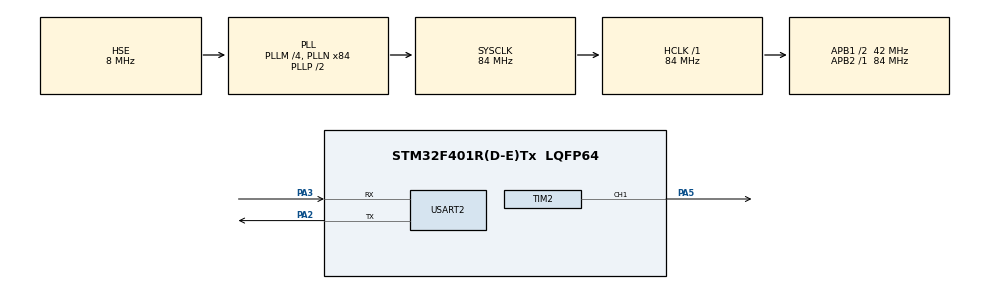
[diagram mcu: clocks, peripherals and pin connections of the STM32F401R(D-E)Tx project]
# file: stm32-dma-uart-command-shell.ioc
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Dma.Request0=USART2_RX
Dma.Request1=USART2_TX
Dma.USART2_RX.0.Direction=DMA_PERIPH_TO_MEMORY
Dma.USART2_RX.0.FIFOMode=DMA_FIFOMODE_DISABLE
Dma.USART2_RX.0.Instance=DMA1_Stream5
Dma.USART2_RX.0.MemDataAlignment=DMA_MDATAALIGN_BYTE
Dma.USART2_RX.0.MemInc=DMA_MINC_ENABLE
Dma.USART2_RX.0.Mode=DMA_CIRCULAR
Dma.USART2_RX.0.PeriphDataAlignment=DMA_PDATAALIGN_BYTE
Dma.USART2_RX.0.PeriphInc=DMA_PINC_DISABLE
Dma.USART2_RX.0.Priority=DMA_PRIORITY_LOW
Dma.USART2_TX.1.Direction=DMA_MEMORY_TO_PERIPH
Dma.USART2_TX.1.FIFOMode=DMA_FIFOMODE_DISABLE
Dma.USART2_TX.1.Instance=DMA1_Stream6
Dma.USART2_TX.1.MemDataAlignment=DMA_MDATAALIGN_BYTE
Dma.USART2_TX.1.MemInc=DMA_MINC_ENABLE
Dma.USART2_TX.1.Mode=DMA_NORMAL
Dma.USART2_TX.1.PeriphDataAlignment=DMA_PDATAALIGN_BYTE
Dma.USART2_TX.1.PeriphInc=DMA_PINC_DISABLE
Dma.USART2_TX.1.Priority=DMA_PRIORITY_LOW
Mcu.Family=STM32F4
Mcu.Name=STM32F401R(D-E)Tx
Mcu.Package=LQFP64
NVIC.DMA1_Stream5_IRQn=true\:0\:0\:false\:false\:true\:false\:true\:true
NVIC.DMA1_Stream6_IRQn=true\:0\:0\:false\:false\:true\:false\:true\:true
NVIC.PriorityGroup=NVIC_PRIORITYGROUP_4
NVIC.TIM2_IRQn=true\:0\:0\:false\:false\:true\:true\:true\:true
NVIC.TIM3_IRQn=true\:0\:0\:false\:false\:true\:true\:true\:true
NVIC.USART2_IRQn=true\:0\:0\:false\:false\:true\:true\:true\:true
PA13.Mode=Serial_Wire
PA13.Signal=SYS_JTMS-SWDIO
PA14.Mode=Serial_Wire
PA14.Signal=SYS_JTCK-SWCLK
PA2.Mode=Asynchronous
PA2.Signal=USART2_TX
PA3.Mode=Asynchronous
PA3.Signal=USART2_RX
PA5.Signal=S_TIM2_CH1_ETR
PH0\ -\ OSC_IN.Mode=HSE-External-Oscillator
PH0\ -\ OSC_IN.Signal=RCC_OSC_IN
PH1\ -\ OSC_OUT.Mode=HSE-External-Oscillator
PH1\ -\ OSC_OUT.Signal=RCC_OSC_OUT
ProjectManager.HeapSize=0x200
ProjectManager.StackSize=0x400
ProjectManager.TargetToolchain=STM32CubeIDE
RCC.48MHZClocksFreq_Value=42000000
RCC.AHBFreq_Value=84000000
RCC.APB1CLKDivider=RCC_HCLK_DIV2
RCC.APB1Freq_Value=42000000
RCC.APB1TimFreq_Value=84000000
RCC.APB2Freq_Value=84000000
RCC.APB2TimFreq_Value=84000000
RCC.CortexFreq_Value=84000000
RCC.HCLKFreq_Value=84000000
RCC.HSE_VALUE=8000000
RCC.HSI_VALUE=16000000
RCC.LSE_VALUE=32768
RCC.PLLM=4
RCC.PLLN=84
RCC.PLLSourceVirtual=RCC_PLLSOURCE_HSE
RCC.SYSCLKFreq_VALUE=84000000
RCC.SYSCLKSource=RCC_SYSCLKSOURCE_PLLCLK
RCC.VCOOutputFreq_Value=168000000
SH.S_TIM2_CH1_ETR.0=TIM2_CH1,PWM Generation1 CH1
TIM2.AutoReloadPreload=TIM_AUTORELOAD_PRELOAD_ENABLE
TIM2.Channel-PWM\ Generation1\ CH1=TIM_CHANNEL_1
TIM2.Period=99
TIM2.Prescaler=839
TIM2.Pulse-PWM\ Generation1\ CH1=3250
TIM3.AutoReloadPreload=TIM_AUTORELOAD_PRELOAD_ENABLE
TIM3.Period=4999
TIM3.Prescaler=8399
USART2.VirtualMode=VM_ASYNC
VP_TIM2_VS_ClockSourceINT.Mode=Internal
VP_TIM3_VS_ClockSourceINT.Mode=Internal
board=custom

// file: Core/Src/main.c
/* USER CODE BEGIN Header */
/**
  ******************************************************************************
  * @file           : main.c
  * @brief          : UART command shell using DMA, between STM32F401RE and St-Link virtual COM port.
  * 				  Button Input.
  * @author			: Omar Ahmed
  ******************************************************************************
  * @details
  * An interactive command shell giving users control over the on-board LED (LD2, PA5)
  * blink rate (ms) and brightness (PWM)) independently.
  * TIM2_CH1 drives the PWM for brightness, and TIM3 sets the blink interval in milliseconds.
  * In addition, it creates feedback responses and status messages.
  *
  * Communication is handled through DMA1 stream 6 for TX and stream 5 for RX,
  * which operates in circular mode, storing the received messages in a ring buffer.
  * The end of each message is detected by the USART IDLE interrupt.
  *
  * Commands:
  * - help
  * - pwm <0-100>
  * - blink <ms>
  * - status
  *
  * Target: NUCLEO-F401RE (STM32F401RE, ARM Cortex-M4, 84 MHz)
  *
  *
  ******************************************************************************
  */
/* USER CODE END Header */
#include "main.h"

/* USER CODE BEGIN Includes */
#include <string.h>		// Byte and string manipulation
#include <stdio.h>		// Declares vsnprintf, used in shell_printf
#include <stdarg.h>		// Standard arguments, machinery for variadic functions.
#include <stdlib.h>		// Standard library.
/* USER CODE END Includes */

/* USER CODE BEGIN PD */
#define RX_BUFFER_SIZE	64
#define TX_BUFFER_SIZE	256
#define MSG_LEN_MAX	64
#define BLINK_MS_MAX	6553		// TIM3 ARR is 16-bit --> 65535 // 1 ARR

/* USER CODE END PD */

TIM_HandleTypeDef htim2;
TIM_HandleTypeDef htim3;

UART_HandleTypeDef huart2;
DMA_HandleTypeDef hdma_usart2_rx;
DMA_HandleTypeDef hdma_usart2_tx;

/* USER CODE BEGIN PV */
// UART receive
extern volatile uint8_t rx_ready;
static uint8_t rx_buffer[RX_BUFFER_SIZE];
static char tx_buffer[TX_BUFFER_SIZE];

static volatile uint16_t rx_tail = 0;
static volatile uint16_t rx_head = 0;

static char rx_msg[MSG_LEN_MAX];
static uint16_t rx_msg_len = 0;

// LED state
static volatile uint8_t blink_on = 1;
static volatile uint16_t blink_ms = 0;	// Size needs to match resigters of TIM3
static volatile uint32_t duty_cycle = 50;

/* USER CODE END PV */

void SystemClock_Config(void);
static void MX_GPIO_Init(void);
static void MX_DMA_Init(void);
static void MX_TIM2_Init(void);
static void MX_USART2_UART_Init(void);
static void MX_TIM3_Init(void);
/* USER CODE BEGIN PFP */
void SystemClock_Config(void);
static void MX_GPIO_Init(void);
static void MX_DMA_Init(void);
static void MX_TIM2_Init(void);
static void MX_USART2_UART_Init(void);
static void MX_TIM3_Init(void);
static void UART_Recieve_Start(void);
static void shell_poll(void);
static void shell_execute(char *msg);
static void shell_printf(const char *msg, ...);		// ... is ellipsis. variadic function --> accepts any number of additional arguments
static int parse_int(char *str, uint32_t *val);
static void led_set_pwm(void);
static void led_set_blink(uint16_t ms);
/* USER CODE BEGIN PFP */
/* USER CODE END PFP */

/* USER CODE BEGIN 0 */

/**
  * @brief  Pol what is received in rx_buffer and hand it to shell_execute.
  */
static void shell_poll(void){
	// Buffer size - NDTR, to get where the recieve msg stopped.
	// NDTR is updated continously.
	rx_head = RX_BUFFER_SIZE - (uint16_t)__HAL_DMA_GET_COUNTER(huart2.hdmarx);

	while (rx_tail != rx_head){			// tail = head when a msg is complete

		char c = rx_buffer[rx_tail];
		rx_tail = (rx_tail+1) % RX_BUFFER_SIZE; 	// Increment tail. Wrap at buffer end.

		if (c == '\r' || c == '\n'){		// When a msg is done
			if (rx_msg_len>0){
				rx_msg[rx_msg_len]= '\0';
				shell_execute(rx_msg);
				rx_msg_len = 0;
			}
		}
		else if (rx_msg_len < (MSG_LEN_MAX - 1)){
			rx_msg[rx_msg_len] = c;
			rx_msg_len++;
		}
		else{
			rx_msg_len = 0;	// Clear the rest of the line in overflow msgs
		}
	}
}

/**
  * @brief  Chech content of received msg, act on it, and print a response.
  */
void static shell_execute(char *msg){

	uint32_t value = 0;		// stroul return unsigned long, which is 32 bits on ARM32 M4

	// Check msg
	// help
	if(strncmp(msg, "help",4)==0){
		shell_printf("\r\n"
					"pwm <0-100>		brightness %% duty cycle \r\n"
					"blink <ms>		blink half-period, 0 = steady on\r\n"
					"status			current settings\r\n"
					"help			this text\r\n\r\n");
	} // pmw <0-100>
	else if (strncmp(msg, "pwm", 3)==0){
		if(!parse_int(msg+3, &value) || value > 100){
			shell_printf("Error: invalid pwm value, expects <0-100>!\r\n\r\n");
		}
		else if(value<=100){
			duty_cycle = value;
			led_set_pwm();
			shell_printf("Brightness set to %u%%!\r\n\r\n", duty_cycle);
		}

	} // blink <0-100>
	else if (strncmp(msg, "blink",5)==0){
		if (!parse_int(msg+5, &value) || value>	6553){		// TIM3 ARR is 16-bit --> 65535 // 1 ARR)
			shell_printf("Error: invalid brightness, expects 0-%u\r\n\r\n", BLINK_MS_MAX);
		}
		else if(value == 0){
			led_set_blink(0);
			shell_printf("Blinking off!\r\n\r\n");

		}
		else{
			led_set_blink((uint16_t) value);
			shell_printf("Blink half-period set to %u ms!\r\n\r\n", value);
		}
	} // status
	else if (strncmp(msg, "status", 6)==0){
		shell_printf("Brightness: %u%%\r\n", duty_cycle);
		shell_printf("Blink half-period: %u ms", blink_ms);

	}
	else{
		shell_printf("Error: unknown command!\r\n\r\n");
	}
}

/**
  * @brief  Parse a decimal value from a string and reject any trailing junk
  * @retval int, 1 on success, 0 on failure.
  */
static int parse_int(char *str, uint32_t *val){

	uint32_t v;		// uint32_t is same size as unsigned long on Cortex M4
	char *end;

	while (*str == ' '){
		str++;
	}
	if(*str<'0' || *str>'9'){
		return 0;
	}

	v=strtoul(str, &end, 10);

	while (*end == ' '){
		end++;
	}

	if (*end!='\0'){
		return 0;

	}

	*val = v;
	return 1;
}

/**
  * @brief  Formats a message and hand it to the TX DMA.
  */

static void shell_printf(const char *str, ...){

    va_list args;   // A type for handling the arguments represented by ..., it iterates over the additional arguments
    int len;

    while (huart2.gState != HAL_UART_STATE_READY){
        // Wait until UART is ready for another operation after the latest HAL_UART_Transmit_DMA
        // Acceptable because it is only called in the main loop
    }

    // Intialize args --> args-> first agrument after str (the last named argument of the function)
    va_start(args, str);        // Gives vsnprint access to the arguments supplied through ...

    // Formulate the arguments into a string buffer with a max.
    len = vsnprintf(tx_buffer, TX_BUFFER_SIZE, str, args);        // Difference between snprintf is that it accepts vardiac (accepts additional arguments)
                                                               // Len recieves the bytes written or would have been written if the buffer is not long enough in the buffer. (minus 1(\0))
    va_end(args);      // Finished using va_start
    if (len > 0){
        if(len> (int) TX_BUFFER_SIZE){
            len = (int) TX_BUFFER_SIZE;
        }
        // Starts the transmission and returns before all the bytes have physically been transmitted.
        HAL_UART_Transmit_DMA(&huart2, (uint8_t*)tx_buffer, (uint16_t) len);
    }

}

/**
  * @brief  Updates the PWM duty cycle in the capture compare register
  */
static void led_set_pwm(void){
    uint32_t arr = __HAL_TIM_GET_AUTORELOAD(&htim2);
    uint32_t crr = 0;

    if(blink_on){
        crr = ((arr+1)*(uint32_t)duty_cycle/100);
    }

    __HAL_TIM_SET_COMPARE(&htim2, TIM_CHANNEL_1, crr);

}

/**
  * @brief  Updates the blink half-period.
  */
static void led_set_blink(uint16_t ms){

    blink_ms = ms;  // Take a copy of current blink half-period
    if(ms==0){
        HAL_TIM_Base_Stop_IT(&htim3);    // Stop TIM3 interrupt
        blink_on = 1;           // Must be set to 1 in case TIM3 was stopped during the off phase, leaving crr 0 in led_set_pwm forever.
    }
    else{
        __HAL_TIM_SET_AUTORELOAD(&htim3, (uint32_t) ms*10 - 1);   // Update auto-reload. With 100KHz, ARR = ms*10 -10
        __HAL_TIM_SET_COUNTER(&htim3,0);    // Reset counter
        blink_on = 1;
        HAL_TIM_Base_Start_IT(&htim3);   // Enable interrupt and start counter
    }
    led_set_pwm();

}

// TIM3 toggles blink_on to control whether CCR get the latest value or a 0 through its interrupt. This approach was chosen over the also-valid alternative TIM3 directly controlling PA5(LED),
// because the pin would have to be reconfigured between alternate fucntion and normal output during runtime.

/**
  * @brief  TIM3 update:toggles blink_on to control whether CCR get the latest value or a 0 through its interrupt.
  */
void HAL_TIM_PeriodElapsedCallback(TIM_HandleTypeDef *htim){

    if(htim->Instance == TIM3){
    	blink_on ^= 1;
    	led_set_pwm();
    }
}

/**
  * @brief  Recover from receive errors. Restart the UART
  */
void HAL_UART_ErrorCallback(UART_HandleTypeDef *huart){

    if(huart->Instance == USART2){
        __HAL_UART_CLEAR_OREFLAG(huart);    // A new byte finished arriving in the shift register before the previous one was read out of DR
        __HAL_UART_CLEAR_NEFLAG(huart);     // If the three samples in the middle of sampling disagree, the bit was noisy
        __HAL_UART_CLEAR_FEFLAG(huart);     // Frame error: stop bit was where it should not be

        if (huart->RxState != HAL_UART_STATE_BUSY_RX)
        {
        UART_Recieve_Start();
        }
    }
}

/**
  * @brief  UART nterrupt call back function
  * @retval int
  */
void HAL_UARTEx_RxEventCallback(UART_HandleTypeDef *huart, uint16_t size){  //size represents number of bytes received when the callback is called

	if(huart->Instance == USART2){
	rx_ready = 1;
	HAL_UARTEx_ReceiveToIdle_DMA(&huart2, rx_buffer, RX_BUFFER_SIZE); // Call interrupt again to continue receiving data since it was disabled after calling the callback
	}
}

/**
  * @brief  Intialize recieve on the UART through DMA1. Always running.
  */

static void UART_Recieve_Start(void){
	rx_tail = 0;
	rx_msg_len = 0;
	HAL_UARTEx_ReceiveToIdle_DMA(&huart2, rx_buffer, RX_BUFFER_SIZE); // Interrupt fires when idel or when data is more than size
}

/* USER CODE END 0 */

int main(void)
{

  /* MCU Configuration--------------------------------------------------------*/

  /* Reset of all peripherals, Initializes the Flash interface and the Systick. */
  HAL_Init();

  /* Configure the system clock */
  SystemClock_Config();

  /* Initialize all configured peripherals */
  MX_GPIO_Init();
  MX_DMA_Init();
  MX_TIM2_Init();
  MX_USART2_UART_Init();
  MX_TIM3_Init();
  /* USER CODE BEGIN 2 */
  led_set_blink(500);
  UART_Recieve_Start();
  HAL_TIM_PWM_Start(&htim2, TIM_CHANNEL_1);
  led_set_pwm();

  shell_printf("\r\nSTM32F401RE shell ready. Type 'help'.\r\n\r\n");
  /* USER CODE END 2 */

  /* Infinite loop */
  while (1)
  {

    /* USER CODE BEGIN 3 */
	  if (rx_ready){
	  		  rx_ready = 0;
	  	      shell_poll();
	  	    }
  }
  /* USER CODE END 3 */
}

void SystemClock_Config(void)
{
  RCC_OscInitTypeDef RCC_OscInitStruct = {0};
  RCC_ClkInitTypeDef RCC_ClkInitStruct = {0};

  /** Configure the main internal regulator output voltage
  */
  __HAL_RCC_PWR_CLK_ENABLE();
  __HAL_PWR_VOLTAGESCALING_CONFIG(PWR_REGULATOR_VOLTAGE_SCALE2);

  /** Initializes the RCC Oscillators according to the specified parameters
  * in the RCC_OscInitTypeDef structure.
  */
  RCC_OscInitStruct.OscillatorType = RCC_OSCILLATORTYPE_HSE;
  RCC_OscInitStruct.HSEState = RCC_HSE_ON;
  RCC_OscInitStruct.PLL.PLLState = RCC_PLL_ON;
  RCC_OscInitStruct.PLL.PLLSource = RCC_PLLSOURCE_HSE;
  RCC_OscInitStruct.PLL.PLLM = 4;
  RCC_OscInitStruct.PLL.PLLN = 84;
  RCC_OscInitStruct.PLL.PLLP = RCC_PLLP_DIV2;
  RCC_OscInitStruct.PLL.PLLQ = 4;
  if (HAL_RCC_OscConfig(&RCC_OscInitStruct) != HAL_OK)
  {
    Error_Handler();
  }

  /** Initializes the CPU, AHB and APB buses clocks
  */
  RCC_ClkInitStruct.ClockType = RCC_CLOCKTYPE_HCLK|RCC_CLOCKTYPE_SYSCLK
                              |RCC_CLOCKTYPE_PCLK1|RCC_CLOCKTYPE_PCLK2;
  RCC_ClkInitStruct.SYSCLKSource = RCC_SYSCLKSOURCE_PLLCLK;
  RCC_ClkInitStruct.AHBCLKDivider = RCC_SYSCLK_DIV1;
  RCC_ClkInitStruct.APB1CLKDivider = RCC_HCLK_DIV2;
  RCC_ClkInitStruct.APB2CLKDivider = RCC_HCLK_DIV1;

  if (HAL_RCC_ClockConfig(&RCC_ClkInitStruct, FLASH_LATENCY_2) != HAL_OK)
  {
    Error_Handler();
  }
}

static void MX_TIM2_Init(void)
{

  TIM_ClockConfigTypeDef sClockSourceConfig = {0};
  TIM_MasterConfigTypeDef sMasterConfig = {0};
  TIM_OC_InitTypeDef sConfigOC = {0};

  htim2.Instance = TIM2;
  htim2.Init.Prescaler = 839;
  htim2.Init.CounterMode = TIM_COUNTERMODE_UP;
  htim2.Init.Period = 99;
  htim2.Init.ClockDivision = TIM_CLOCKDIVISION_DIV1;
  htim2.Init.AutoReloadPreload = TIM_AUTORELOAD_PRELOAD_ENABLE;
  if (HAL_TIM_Base_Init(&htim2) != HAL_OK)
  {
    Error_Handler();
  }
  sClockSourceConfig.ClockSource = TIM_CLOCKSOURCE_INTERNAL;
  if (HAL_TIM_ConfigClockSource(&htim2, &sClockSourceConfig) != HAL_OK)
  {
    Error_Handler();
  }
  if (HAL_TIM_PWM_Init(&htim2) != HAL_OK)
  {
    Error_Handler();
  }
  sMasterConfig.MasterOutputTrigger = TIM_TRGO_RESET;
  sMasterConfig.MasterSlaveMode = TIM_MASTERSLAVEMODE_DISABLE;
  if (HAL_TIMEx_MasterConfigSynchronization(&htim2, &sMasterConfig) != HAL_OK)
  {
    Error_Handler();
  }
  sConfigOC.OCMode = TIM_OCMODE_PWM1;
  sConfigOC.Pulse = 3250;
  sConfigOC.OCPolarity = TIM_OCPOLARITY_HIGH;
  sConfigOC.OCFastMode = TIM_OCFAST_DISABLE;
  if (HAL_TIM_PWM_ConfigChannel(&htim2, &sConfigOC, TIM_CHANNEL_1) != HAL_OK)
  {
    Error_Handler();
  }
  HAL_TIM_MspPostInit(&htim2);

}

static void MX_TIM3_Init(void)
{

  TIM_ClockConfigTypeDef sClockSourceConfig = {0};
  TIM_MasterConfigTypeDef sMasterConfig = {0};

  htim3.Instance = TIM3;
  htim3.Init.Prescaler = 8399;
  htim3.Init.CounterMode = TIM_COUNTERMODE_UP;
  htim3.Init.Period = 4999;
  htim3.Init.ClockDivision = TIM_CLOCKDIVISION_DIV1;
  htim3.Init.AutoReloadPreload = TIM_AUTORELOAD_PRELOAD_ENABLE;
  if (HAL_TIM_Base_Init(&htim3) != HAL_OK)
  {
    Error_Handler();
  }
  sClockSourceConfig.ClockSource = TIM_CLOCKSOURCE_INTERNAL;
  if (HAL_TIM_ConfigClockSource(&htim3, &sClockSourceConfig) != HAL_OK)
  {
    Error_Handler();
  }
  sMasterConfig.MasterOutputTrigger = TIM_TRGO_RESET;
  sMasterConfig.MasterSlaveMode = TIM_MASTERSLAVEMODE_DISABLE;
  if (HAL_TIMEx_MasterConfigSynchronization(&htim3, &sMasterConfig) != HAL_OK)
  {
    Error_Handler();
  }

}

static void MX_USART2_UART_Init(void)
{

  huart2.Instance = USART2;
  huart2.Init.BaudRate = 115200;
  huart2.Init.WordLength = UART_WORDLENGTH_8B;
  huart2.Init.StopBits = UART_STOPBITS_1;
  huart2.Init.Parity = UART_PARITY_NONE;
  huart2.Init.Mode = UART_MODE_TX_RX;
  huart2.Init.HwFlowCtl = UART_HWCONTROL_NONE;
  huart2.Init.OverSampling = UART_OVERSAMPLING_16;
  if (HAL_UART_Init(&huart2) != HAL_OK)
  {
    Error_Handler();
  }

}

static void MX_DMA_Init(void)
{

  /* DMA controller clock enable */
  __HAL_RCC_DMA1_CLK_ENABLE();

  /* DMA interrupt init */
  /* DMA1_Stream5_IRQn interrupt configuration */
  HAL_NVIC_SetPriority(DMA1_Stream5_IRQn, 0, 0);
  HAL_NVIC_EnableIRQ(DMA1_Stream5_IRQn);
  /* DMA1_Stream6_IRQn interrupt configuration */
  HAL_NVIC_SetPriority(DMA1_Stream6_IRQn, 0, 0);
  HAL_NVIC_EnableIRQ(DMA1_Stream6_IRQn);

}

static void MX_GPIO_Init(void)
{

  /* GPIO Ports Clock Enable */
  __HAL_RCC_GPIOH_CLK_ENABLE();
  __HAL_RCC_GPIOA_CLK_ENABLE();

}

void Error_Handler(void)
{
  __disable_irq();
  while (1)
  {
  }
}
